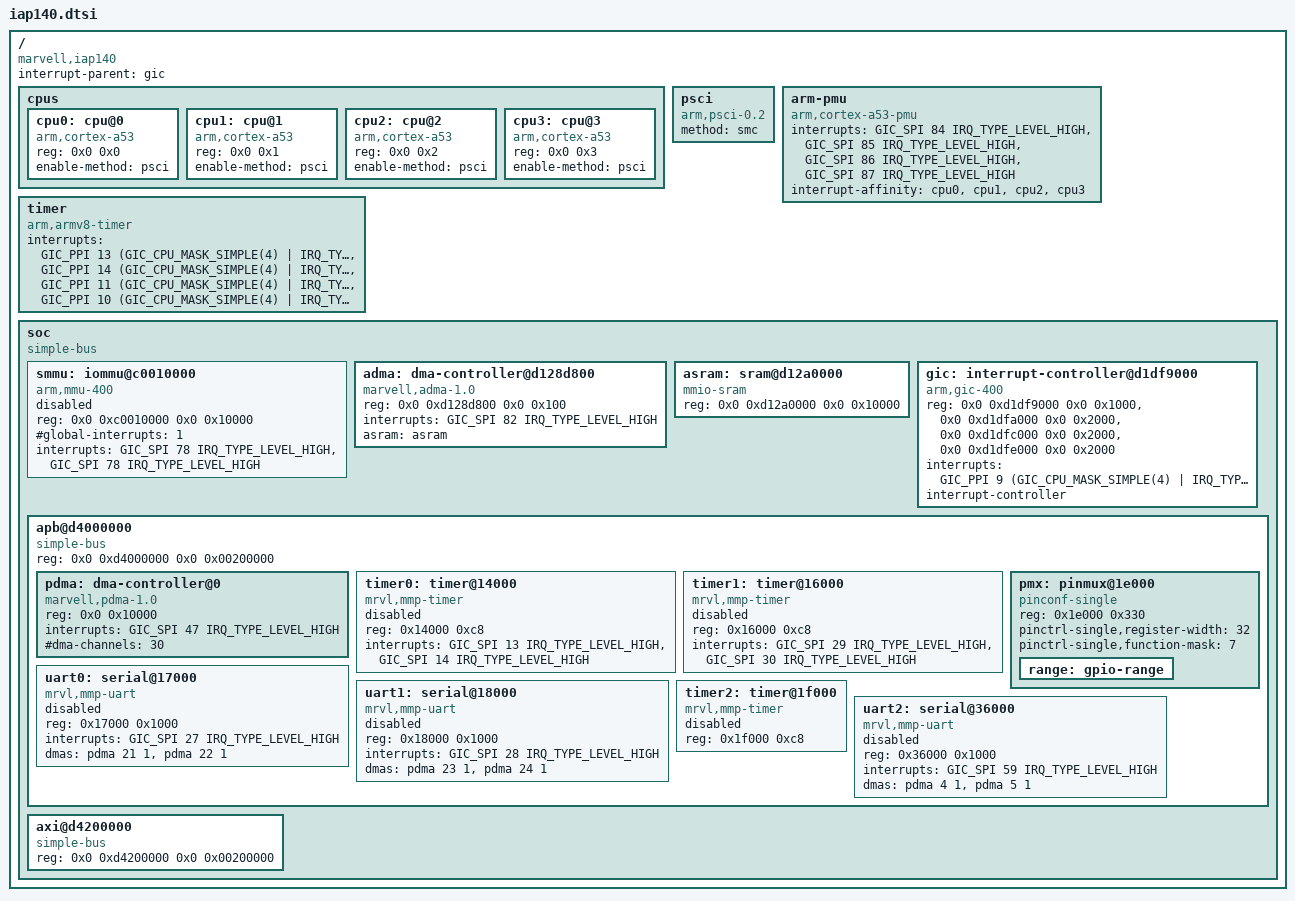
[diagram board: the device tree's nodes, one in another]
/*
 * Copyright (c) 2016-2017 Andreas Färber
 *
 * This file is dual-licensed: you can use it either under the terms
 * of the GPL or the X11 license, at your option. Note that this dual
 * licensing only applies to this file, and not this project as a
 * whole.
 *
 *  a) This library is free software; you can redistribute it and/or
 *     modify it under the terms of the GNU General Public License as
 *     published by the Free Software Foundation; either version 2 of the
 *     License, or (at your option) any later version.
 *
 *     This library is distributed in the hope that it will be useful,
 *     but WITHOUT ANY WARRANTY; without even the implied warranty of
 *     MERCHANTABILITY or FITNESS FOR A PARTICULAR PURPOSE.  See the
 *     GNU General Public License for more details.
 *
 * Or, alternatively,
 *
 *  b) Permission is hereby granted, free of charge, to any person
 *     obtaining a copy of this software and associated documentation
 *     files (the "Software"), to deal in the Software without
 *     restriction, including without limitation the rights to use,
 *     copy, modify, merge, publish, distribute, sublicense, and/or
 *     sell copies of the Software, and to permit persons to whom the
 *     Software is furnished to do so, subject to the following
 *     conditions:
 *
 *     The above copyright notice and this permission notice shall be
 *     included in all copies or substantial portions of the Software.
 *
 *     THE SOFTWARE IS PROVIDED "AS IS", WITHOUT WARRANTY OF ANY KIND,
 *     EXPRESS OR IMPLIED, INCLUDING BUT NOT LIMITED TO THE WARRANTIES
 *     OF MERCHANTABILITY, FITNESS FOR A PARTICULAR PURPOSE AND
 *     NONINFRINGEMENT. IN NO EVENT SHALL THE AUTHORS OR COPYRIGHT
 *     HOLDERS BE LIABLE FOR ANY CLAIM, DAMAGES OR OTHER LIABILITY,
 *     WHETHER IN AN ACTION OF CONTRACT, TORT OR OTHERWISE, ARISING
 *     FROM, OUT OF OR IN CONNECTION WITH THE SOFTWARE OR THE USE OR
 *     OTHER DEALINGS IN THE SOFTWARE.
 */

#include <dt-bindings/interrupt-controller/arm-gic.h>

/ {
	compatible = "marvell,iap140";
	interrupt-parent = <&gic>;
	#address-cells = <2>;
	#size-cells = <2>;

	cpus {
		#address-cells = <2>;
		#size-cells = <0>;

		cpu0: cpu@0 {
			device_type = "cpu";
			compatible = "arm,cortex-a53", "arm,armv8";
			reg = <0x0 0x0>;
			enable-method = "psci";
		};

		cpu1: cpu@1 {
			device_type = "cpu";
			compatible = "arm,cortex-a53", "arm,armv8";
			reg = <0x0 0x1>;
			enable-method = "psci";
		};

		cpu2: cpu@2 {
			device_type = "cpu";
			compatible = "arm,cortex-a53", "arm,armv8";
			reg = <0x0 0x2>;
			enable-method = "psci";
		};

		cpu3: cpu@3 {
			device_type = "cpu";
			compatible = "arm,cortex-a53", "arm,armv8";
			reg = <0x0 0x3>;
			enable-method = "psci";
		};
	};

	psci {
		compatible = "arm,psci-0.2";
		method = "smc";
	};

	arm-pmu {
		compatible = "arm,cortex-a53-pmu";
		interrupts = <GIC_SPI 84 IRQ_TYPE_LEVEL_HIGH>,
		             <GIC_SPI 85 IRQ_TYPE_LEVEL_HIGH>,
		             <GIC_SPI 86 IRQ_TYPE_LEVEL_HIGH>,
		             <GIC_SPI 87 IRQ_TYPE_LEVEL_HIGH>;
		interrupt-affinity = <&cpu0>, <&cpu1>, <&cpu2>, <&cpu3>;
	};

	timer {
		compatible = "arm,armv8-timer";
		interrupts = <GIC_PPI 13
			(GIC_CPU_MASK_SIMPLE(4) | IRQ_TYPE_LEVEL_LOW)>,
			     <GIC_PPI 14
			(GIC_CPU_MASK_SIMPLE(4) | IRQ_TYPE_LEVEL_LOW)>,
			     <GIC_PPI 11
			(GIC_CPU_MASK_SIMPLE(4) | IRQ_TYPE_LEVEL_LOW)>,
			     <GIC_PPI 10
			(GIC_CPU_MASK_SIMPLE(4) | IRQ_TYPE_LEVEL_LOW)>;
	};

	soc {
		compatible = "simple-bus";
		#address-cells = <2>;
		#size-cells = <2>;
		ranges;

		smmu: iommu@c0010000 {
			compatible = "arm,mmu-400";
			reg = <0x0 0xc0010000 0x0 0x10000>;
			#global-interrupts = <1>;
			interrupts = <GIC_SPI 78 IRQ_TYPE_LEVEL_HIGH>,
			             <GIC_SPI 78 IRQ_TYPE_LEVEL_HIGH>;
			status = "disabled";
		};

		adma: dma-controller@d128d800 {
			compatible = "marvell,adma-1.0";
			reg = <0x0 0xd128d800 0x0 0x100>;
			interrupts = <GIC_SPI 82 IRQ_TYPE_LEVEL_HIGH>;
			asram = <&asram>;
		};

		asram: sram@d12a0000 {
			compatible = "mmio-sram";
			reg = <0x0 0xd12a0000 0x0 0x10000>;
		};

		gic: interrupt-controller@d1df9000 {
			compatible = "arm,gic-400";
			reg = <0x0 0xd1df9000 0x0 0x1000>,
			      <0x0 0xd1dfa000 0x0 0x2000>,
			      <0x0 0xd1dfc000 0x0 0x2000>,
			      <0x0 0xd1dfe000 0x0 0x2000>;
			interrupts = <GIC_PPI 9 (GIC_CPU_MASK_SIMPLE(4) | IRQ_TYPE_LEVEL_LOW)>;
			interrupt-controller;
			#interrupt-cells = <3>;
		};

		apb@d4000000 {
			compatible = "simple-bus";
			reg = <0x0 0xd4000000 0x0 0x00200000>;
			#address-cells = <1>;
			#size-cells = <1>;
			ranges = <0x0 0x0 0xd4000000 0x00200000>;

			pdma: dma-controller@0 {
				compatible = "marvell,pdma-1.0";
				reg = <0x0 0x10000>;
				interrupts = <GIC_SPI 47 IRQ_TYPE_LEVEL_HIGH>;
				#dma-cells = <2>;
				#dma-channels = <30>;
			};

			timer0: timer@14000 {
				compatible = "mrvl,mmp-timer";
				reg = <0x14000 0xc8>;
				interrupts = <GIC_SPI 13 IRQ_TYPE_LEVEL_HIGH>,
				             <GIC_SPI 14 IRQ_TYPE_LEVEL_HIGH>;
				status = "disabled";
			};

			timer1: timer@16000 {
				compatible = "mrvl,mmp-timer";
				reg = <0x16000 0xc8>;
				interrupts = <GIC_SPI 29 IRQ_TYPE_LEVEL_HIGH>,
				             <GIC_SPI 30 IRQ_TYPE_LEVEL_HIGH>;
				status = "disabled";
			};

			uart0: serial@17000 {
				compatible = "mrvl,mmp-uart";
				reg = <0x17000 0x1000>;
				interrupts = <GIC_SPI 27 IRQ_TYPE_LEVEL_HIGH>;
				dmas = <&pdma 21 1>,
				       <&pdma 22 1>;
				dma-names = "rx", "tx";
				status = "disabled";
			};

			uart1: serial@18000 {
				compatible = "mrvl,mmp-uart";
				reg = <0x18000 0x1000>;
				interrupts = <GIC_SPI 28 IRQ_TYPE_LEVEL_HIGH>;
				dmas = <&pdma 23 1>,
				       <&pdma 24 1>;
				dma-names = "rx", "tx";
				status = "disabled";
			};

			pmx: pinmux@1e000 {
				compatible = "pinconf-single";
				reg = <0x1e000 0x330>;
				#address-cells = <1>;
				#size-cells = <1>;
				#gpio-range-cells = <3>;
				ranges;

				#pinctrl-cells = <1>;
				pinctrl-single,register-width = <32>;
				pinctrl-single,function-mask = <7>;

				range: gpio-range {
					#pinctrl-single,gpio-range-cells = <3>;
				};
			};

			timer2: timer@1f000 {
				compatible = "mrvl,mmp-timer";
				reg = <0x1f000 0xc8>;
				status = "disabled";
			};

			uart2: serial@36000 {
				compatible = "mrvl,mmp-uart";
				reg = <0x36000 0x1000>;
				interrupts = <GIC_SPI 59 IRQ_TYPE_LEVEL_HIGH>;
				dmas = <&pdma 4 1>,
				       <&pdma 5 1>;
				dma-names = "rx", "tx";
				status = "disabled";
			};
		};

		axi@d4200000 {
			compatible = "simple-bus";
			reg = <0x0 0xd4200000 0x0 0x00200000>;
			#address-cells = <1>;
			#size-cells = <1>;
			ranges = <0x0 0x0 0xd4200000 0x00200000>;
		};
	};
};
